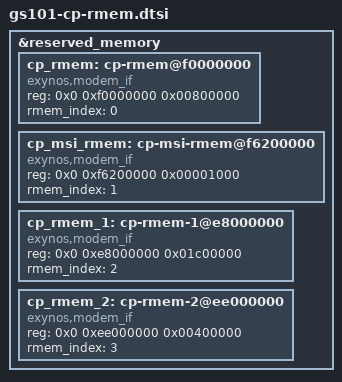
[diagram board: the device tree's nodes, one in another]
// SPDX-License-Identifier: GPL-2.0-only
/*
 * CP reserved memory, split out of gs101-cp.dtsi so it can be tested on its
 * own. Roughly 40 MB out of the first 2 GB bank, which runs 0x80000000 to
 * 0x100000000.
 */

&reserved_memory {
	cp_rmem: cp-rmem@f0000000 {
		compatible = "exynos,modem_if";
		reg = <0x0 0xf0000000 0x00800000>;
		rmem_index = <0>;
	};

	cp_msi_rmem: cp-msi-rmem@f6200000 {
		compatible = "exynos,modem_if";
		reg = <0x0 0xf6200000 0x00001000>;
		rmem_index = <1>;
	};

	cp_rmem_1: cp-rmem-1@e8000000 {
		compatible = "exynos,modem_if";
		reg = <0x0 0xe8000000 0x01c00000>;
		rmem_index = <2>;
	};

	cp_rmem_2: cp-rmem-2@ee000000 {
		compatible = "exynos,modem_if";
		reg = <0x0 0xee000000 0x00400000>;
		rmem_index = <3>;
	};
};
